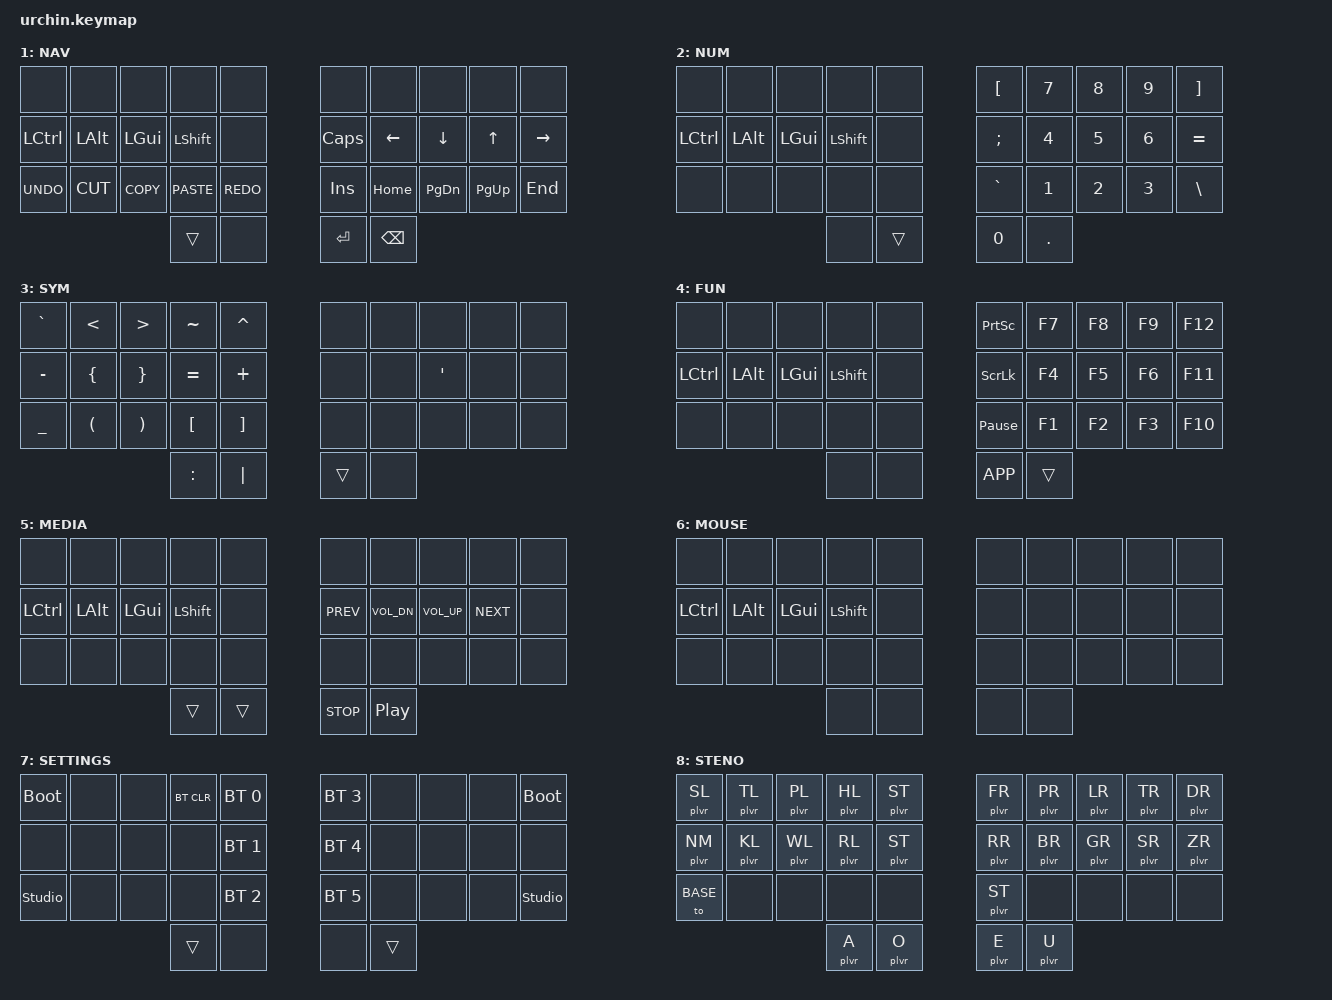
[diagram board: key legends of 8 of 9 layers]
#include <behaviors.dtsi>
#include <dt-bindings/zmk/keys.h>
#include <dt-bindings/zmk/bt.h>
#include <dt-bindings/zmk/plvr.h>

// Layer definitions
#define BASE 0
#define NAV  1
#define NUM  2
#define SYM  3
#define FUN  4
#define MEDIA 5
#define MOUSE 6
#define SETTINGS 7
#define STENO 8

// Homerow mod config (CAGS)
#define HRML(k1,k2,k3,k4) &ht LCTRL k1  &ht LALT k2  &ht LGUI k3  &ht LSHFT k4
#define HRMR(k1,k2,k3,k4) &ht RSHFT k1  &ht RGUI k2  &ht RALT k3  &ht RCTRL k4

/ {
    behaviors {
        ht: hold_tap {
            compatible = "zmk,behavior-hold-tap";
            #binding-cells = <2>;
            flavor = "balanced";
            tapping-term-ms = <280>;
            quick-tap-ms = <175>;
            require-prior-idle-ms = <150>;
            bindings = <&kp>, <&kp>;
            hold-trigger-on-release;
        };

        lt_hp: layer_tap {
            compatible = "zmk,behavior-hold-tap";
            #binding-cells = <2>;
            flavor = "balanced";
            tapping-term-ms = <200>;
            quick-tap-ms = <150>;
            bindings = <&mo>, <&kp>;
        };

        lt_sk: layer_tap_sticky {
            compatible = "zmk,behavior-hold-tap";
            #binding-cells = <2>;
            flavor = "balanced";
            tapping-term-ms = <200>;
            quick-tap-ms = <150>;
            bindings = <&mo>, <&sk>;
        };
    };

    combos {
        compatible = "zmk,combos";
        
        // J + K = Escape
        combo_esc {
            timeout-ms = <50>;
            key-positions = <16 17>;
            bindings = <&kp ESC>;
            layers = <BASE>;
        };

        // Both left thumbs = Media
        combo_media {
            timeout-ms = <50>;
            key-positions = <30 31>;
            bindings = <&mo MEDIA>;
        };

        // Both right thumbs = Mouse
        combo_mouse {
            timeout-ms = <50>;
            key-positions = <32 33>;
            bindings = <&mo MOUSE>;
        };

        // Both inner thumbs = Settings
        combo_settings {
            timeout-ms = <50>;
            key-positions = <31 32>;
            bindings = <&mo SETTINGS>;
        };

        // Both outer thumbs = Steno
        combo_steno {
            timeout-ms = <50>;
            key-positions = <30 33>;
            bindings = <&to STENO>;
        };
    };

    keymap {
        compatible = "zmk,keymap";

        base_layer {
            display-name = "BASE";
            bindings = <
                &kp Q       &kp W      &kp E      &kp R       &kp T          &kp Y      &kp U       &kp I      &kp O      &kp P
                HRML(A,         S,         D,         F)      &kp G          &kp H      HRMR(J,         K,         L,         SEMI)
                &kp Z       &kp X      &kp C      &kp V       &kp B          &kp N      &kp M       &kp COMMA  &kp DOT    &kp FSLH
                                          &lt_hp NAV BSPC    &lt_sk NUM TAB &lt_hp SYM SPACE &lt_hp FUN RET
            >;
        };

        nav_layer {
            display-name = "NAV";
            bindings = <
                &none       &none      &none      &none       &none          &none      &none       &none      &none      &none
                &kp LCTRL   &kp LALT   &kp LGUI   &kp LSHFT   &none          &kp CAPS   &kp LEFT    &kp DOWN   &kp UP     &kp RIGHT
                &kp K_UNDO  &kp K_CUT  &kp K_COPY &kp K_PASTE &kp K_REDO     &kp INS    &kp HOME    &kp PG_DN  &kp PG_UP  &kp END
                                                  &trans      &none          &kp RET    &kp BSPC
            >;
        };

        num_layer {
            display-name = "NUM";
            bindings = <
                &none       &none      &none      &none       &none          &kp LBKT   &kp N7      &kp N8     &kp N9     &kp RBKT
                &kp LCTRL   &kp LALT   &kp LGUI   &kp LSHFT   &none          &kp SEMI   &kp N4      &kp N5     &kp N6     &kp EQUAL
                &none       &none      &none      &none       &none          &kp GRAVE  &kp N1      &kp N2     &kp N3     &kp BSLH
                                                  &none       &trans         &kp N0     &kp DOT
            >;
        };

        sym_layer {
            display-name = "SYM";
            bindings = <
                &kp GRAVE   &kp LT     &kp GT     &kp TILDE   &kp CARET      &none      &none       &none      &none      &none
                &kp MINUS   &kp LBRC   &kp RBRC   &kp EQUAL   &kp PLUS       &none      &none       &kp APOS      &none      &none
                &kp UNDER   &kp LPAR   &kp RPAR   &kp LBKT    &kp RBKT       &none      &none       &none      &none      &none
                                                  &kp COLON   &kp PIPE       &trans     &none
            >;
        };

        fun_layer {
            display-name = "FUN";
            bindings = <
                &none       &none      &none      &none       &none          &kp PSCRN  &kp F7      &kp F8     &kp F9     &kp F12
                &kp LCTRL   &kp LALT   &kp LGUI   &kp LSHFT   &none          &kp SLCK   &kp F4      &kp F5     &kp F6     &kp F11
                &none       &none      &none      &none       &none          &kp PAUSE_BREAK &kp F1 &kp F2     &kp F3     &kp F10
                                                  &none       &none          &kp K_APP  &trans
            >;
        };

        media_layer {
            display-name = "MEDIA";
            bindings = <
                &none       &none      &none      &none       &none          &none      &none       &none      &none      &none
                &kp LCTRL   &kp LALT   &kp LGUI   &kp LSHFT   &none          &kp C_PREV &kp C_VOL_DN &kp C_VOL_UP &kp C_NEXT &none
                &none       &none      &none      &none       &none          &none      &none       &none      &none      &none
                                                  &trans      &trans         &kp C_STOP &kp C_PP
            >;
        };

        mouse_layer {
            display-name = "MOUSE";
            bindings = <
                &none       &none      &none      &none       &none          &none      &none       &none      &none      &none
                &kp LCTRL   &kp LALT   &kp LGUI   &kp LSHFT   &none          &none      &none       &none      &none      &none
                &none       &none      &none      &none       &none          &none      &none       &none      &none      &none
                                                  &none       &none          &none      &none
            >;
        };

        settings_layer {
            display-name = "SETTINGS";
            bindings = <
                &bootloader &none      &none      &bt BT_CLR  &bt BT_SEL 0   &bt BT_SEL 3 &none      &none      &none      &bootloader
                &none       &none      &none      &none       &bt BT_SEL 1   &bt BT_SEL 4 &none      &none      &none      &none
                &studio_unlock &none   &none      &none       &bt BT_SEL 2   &bt BT_SEL 5 &none      &none      &none      &studio_unlock
                                                  &trans      &none          &none        &trans
            >;
        };

        steno_layer {
            display-name = "STENO";
            bindings = <
                &plvr SL    &plvr TL   &plvr PL   &plvr HL    &plvr ST       &plvr FR   &plvr PR    &plvr LR   &plvr TR   &plvr DR
                &plvr NM    &plvr KL   &plvr WL   &plvr RL    &plvr ST       &plvr RR   &plvr BR    &plvr GR   &plvr SR   &plvr ZR
                &to BASE    &none      &none      &none       &none          &plvr ST   &none       &none      &none      &none
                                                  &plvr A     &plvr O        &plvr E    &plvr U
            >;
        };
    };
};
